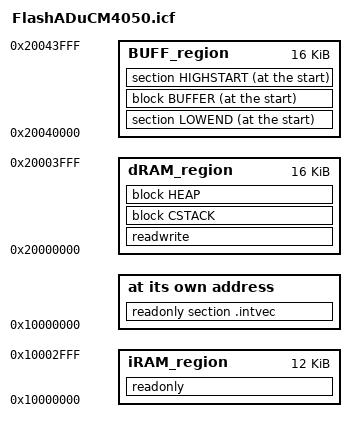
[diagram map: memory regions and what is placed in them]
/*###ICF### Section handled by ICF editor, don't touch! ****/
/*-Editor annotation file-*/
/* IcfEditorFile="$TOOLKIT_DIR$\config\ide\IcfEditor\a_v1_0.xml" */
/*-Specials-*/
define symbol __ICFEDIT_intvec_start__ = 0x10000000;  // Bank1. 12KB ISRAM in default mode.
/*-Memory Regions-*/
define symbol __ICFEDIT_region_ROM_start__  = 0x10000000;  // Bank1. 12KB ISRAM in default mode.
define symbol __ICFEDIT_region_ROM_end__    = 0x10002FFF;
define symbol __ICFEDIT_region_RAM_start__  = 0x20000000;  // Bank0. 16KB DSRAM in all modes.
define symbol __ICFEDIT_region_RAM_end__    = 0x20003FFF;
define symbol __ICFEDIT_region_RAM3_start__ = 0x20040000;  // Bank3. 16KB DSRAM in all modes.
define symbol __ICFEDIT_region_RAM3_end__   = 0x20043FFF;
/*-Sizes-*/
define symbol __ICFEDIT_size_cstack__      = 0x800;
define symbol __ICFEDIT_size_heap__        = 0x800;
/**** End of ICF editor section. ###ICF###*/

define memory mem with size = 4G;
define region iRAM_region   = mem:[from __ICFEDIT_region_ROM_start__    to __ICFEDIT_region_ROM_end__];
define region dRAM_region   = mem:[from __ICFEDIT_region_RAM_start__    to __ICFEDIT_region_RAM_end__];
define region BUFF_region   = mem:[from __ICFEDIT_region_RAM3_start__   to __ICFEDIT_region_RAM3_end__];

define block CSTACK    with alignment = 8, size = __ICFEDIT_size_cstack__   { };
define block HEAP      with alignment = 8, size = __ICFEDIT_size_heap__     { };
define block BUFFER    with alignment = 8, size = 8k     { };  // 1/2 of bank3 for download buffer

// KEEP these blocks, avoiding linker elimination...
keep {
	block CSTACK,
	block HEAP,
    block BUFFER,
};

initialize by copy { readwrite };
do not initialize  { section .noinit };

place at address mem:__ICFEDIT_intvec_start__ { readonly section .intvec };

// iRam placements
place in iRAM_region { readonly };

// dRam placements
place at start of BUFF_region { section LOWEND, block BUFFER, section HIGHSTART };
place in dRAM_region { readwrite, block CSTACK, block HEAP };

